# SPC1068 register map
File version: 20180100_70611510
CPU: CM3 r2p1, little endian, MPU, no FPU, 4 interrupt priority bits
Registers are 32-bit, read-write, reset 0x0 unless marked. A register's access mark holds for its fields unless they carry their own. Offsets are from the block's base; [hi:lo] are bit positions; 'fields as' and 'values as' point back to an identical list.

## I2C
Base 0x40006000
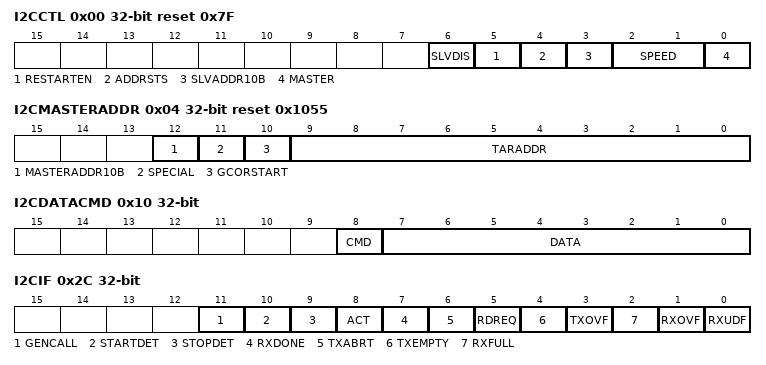
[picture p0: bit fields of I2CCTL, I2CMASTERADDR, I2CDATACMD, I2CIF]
0x00 I2CCTL reset 0x7F — I2C Control Register
  [6] SLVDIS — This bit controls whether I2C has its slave disabled, which means once the presetn signal is applied, then this bit takes on the value of the configuration parameter SLAVE_DISABLE. You have the choice of having the slave enabled or disabled after reset is applied, which means software does not have to configure the slave. By default, the slave is always enabled (in reset state as well). If you need to disable it after reset, set this bit to 1. If this bit is set (slave is disabled), I2C functions only as a master and does not perform any action that requires a slave. NOTE: Software should ensure that if this bit is written with 0, then bit 0 should also be written with a 0.
    0=SLAVE_ENABLE (Slave is enabled); 1=SLAVE_DISABLE (Slave is disabled)
  [5] RESTARTEN — Determines whether RESTART conditions may be sent when acting as a master. Some older slaves do not support handling RESTART conditions; however, RESTART conditions are used in several I2C operations. When RESTART is disabled, the master is prohibited from performing the following functions: - Change direction within a transfer (split) - Send a START BYTE - High-speed mode operation - Combined format transfers in 7-bit addressing modes - Read operation with a 10-bit address - Send multiple bytes per transfer By replacing RESTART condition followed by a STOP and a subsequent START condition, split operations are broken down into multiple I2C transfers. If the above operations are performed, it will result in setting bit 6 (TXABRT) of the I2CRAWIF register.
    0=DISABLE; 1=ENABLE
  [4] ADDRSTS ro — The function of this bit is handled by bit 12 of I2CMASTERADDR register, and becomes a read-only copy.
    0=7BIT_ADDR (7-bit addressing); 1=10BIT_ADDR (10-bit addressing)
  [3] SLVADDR10B — When acting as a slave, this bit controls whether the I2C responds to 7- or 10-bit addresses. 0x0: 7-bit addressing. The I2C ignores transactions that involve 10-bit addressing; for 7-bit addressing, only the lower 7 bits of the I2CSLVADDR register are compared. 0x1: 10-bit addressing. The I2C responds to only 10-bit addressing transfers that match the full 10 bits of the I2CSLVADDR register.
    values as ADDRSTS
  [2:1] SPEED — These bits control at which speed the I2C operates; its setting is relevant only if one is operating the I2C in master mode. Hardware protects against illegal values being programmed by software. This register should be programmed only with a value in the range of 1 to 3; otherwise, hardware updates this register with the value of 3.
    1=100K_BPS (Standard mode (100 kbit/s)); 2=400K_BPS (Fast mode (400 kbit/s)); 3=3400K_BPS (High speed mode (3.4 Mbit/s))
  [0] MASTER — This bit controls whether the I2C master is enabled. NOTE: Software should ensure that if this bit is written with '1' then bit 6 should also be written with a '1'.
    0=DISABLE (Master disabled); 1=ENABLE (Master enabled)
0x04 I2CMASTERADDR reset 0x1055 — I2C Master Address Register
  [12] MASTERADDR10B — This bit controls whether the I2C starts its transfers in 7- or 10-bit addressing mode when acting as a master.
    values as I2CCTL.ADDRSTS
  [11] SPECIAL — This bit indicates whether software performs a General Call or START BYTE command.
    0=DISABLE (Ignore bit 10 GCORSTART and use I2CMASTERADDR normally); 1=ENABLE (Perform special I2C command as specified in GCORSTART bit)
  [10] GCORSTART — If bit 11 (SPECIAL) is set to 1, then this bit indicates whether a General Call or START byte command is to be performed by the I2C.
    0=GENERAL_CALL (General Call Address after issuing a General Call, only writes may be performed. Attempting to issue a read command results in setting bit 6 (TXABRT) of the I2CRAWIF register. The I2C remains in General Call mode until the SPECIAL bit value (bit 11) is cleared); 1=START (START BYTE)
  [9:0] TARADDR — This is the target address for any master transaction. When transmitting a General Call, these bits are ignored. To generate a START BYTE, the CPU needs to write only once into these bits. If the I2CMASTERADDR and I2CSLVADDR are the same, loopback exists but the FIFOs are shared between master and slave, so full loopback is not feasible. Only one direction loopback mode is supported (simplex), not duplex. A master cannot transmit to itself; it can transmit to only a slave.
0x08 I2CSLVADDR reset 0x55 — I2C Slave Address Register
  [9:0] VAL — The VAL holds the slave address when the I2C is operating as a slave. For 7-bit addressing, only VAL[6:0] is used. This register can be written only when the I2C interface is disabled, which corresponds to the I2CENABLE register being set to 0. Writes at other times have no effect. Note: The default values cannot be any of the reserved address locations: that is, 0x00 to 0x07, or 0x78 to 0x7f. The correct operation of the device is not guaranteed if you program the I2CSLVADDR or I2CMASTERADDR to a reserved value.
0x0C I2CHSMADDR reset 0x1 — I2C High Speed Master Mode Code Address Register
  [2:0] VAL — This bit field holds the value of the I2C HS mode master code. HS-mode master codes are reserved 8-bit codes (00001xxx) that are not used for slave addressing or other purposes. Each master has its unique master code; up to eight high-speed mode masters can be present on the same I2C bus system. Valid values are from 0 to 7. This register can be written only when the I2C interface is disabled, which corresponds to the I2CENABLE register being set to 0. Writes at other times have no effect.
0x10 I2CDATACMD — I2C Data Buffer and Command Register
  [8] CMD — This bit controls whether a read or a write is performed. This bit does not control the direction when the I2C acts as a slave. It controls only the direction when it acts as a master. When a command is entered in the TX FIFO, this bit distinguishes the write and read commands. In slavereceiver mode, this bit is a 'don't care' because writes to this register are not required. In slave-transmitter mode, a '0' indicates that CPU data is to be transmitted and as DATA or I2CDATACMD[7:0]. When programming this bit, you should remember the following: attempting to perform a read operation after a General Call command has been sent results in a TXABRT interrupt (bit 6 of the I2CRAWIF register), unless bit 11 (SPECIAL) in the I2CMASTERADDR register has been cleared. If a '1' is written to this bit after receiving a RDREQ interrupt, then a TXABRT interrupt occurs. NOTE: It is possible that while attempting a master I2C read transfer on I2C, a RDREQ interrupt may have occurred simultaneously due to a remote I2C master addressing I2C. In this type of scenario, I2C ignores the I2CDATACMD write, generates a TXABRT interrupt, and waits to service the RDREQ interrupt.
    0=WRITE; 1=READ
  [7:0] DATA — This register contains the data to be transmitted or received on the I2C bus. If you are writing to this register and want to perform a read, bits 7:0 (DATA) are ignored by the I2C. However, when you read this register, these bits return the value of data received on the I2C interface.
0x14 I2CSSHCNT reset 0x1F4 — Standard Speed I2C Clock SCL High Count Register
  [15:0] VAL — This register must be set before any I2C bus transaction can take place to ensure proper I/O timing. This register sets the SCL clock high-period count for standard speed. These values apply only if the ic_clk is set to the given frequency in the table. This register can be written only when the I2C interface is disabled which corresponds to the I2CENABLE register being set to 0. Writes at other times have no effect. The minimum valid value is 6; hardware prevents values less than this being written, and if attempted results in 6 being set. For designs with APB_DATA_WIDTH = 8, the order of programming is important to ensure the correct operation of the I2C. The lower byte must be programmed first. Then the upper byte is programmed.
0x18 I2CSSLCNT reset 0x24C — Standard Speed I2C Clock SCL Low Count Register
  [15:0] VAL — This register must be set before any I2C bus transaction can take place to ensure proper I/O timing. This register sets the SCL clock low period count for standard speed. The table below shows some sample I2CSSLCNT calculations. These values apply only if the ic_clk is set to the given frequency in the table. This register can be written only when the I2C interface is disabled which corresponds to the I2CENABLE register being set to 0. Writes at other times have no effect. The minimum valid value is 8; hardware prevents values less than this being written, and if attempted, results in 8 being set. For designs with APB_DATA_WIDTH = 8, the order of programming is important to ensure the correct operation of I2C. The lower byte must be programmed first, and then the upper byte is programmed.
0x1C I2CFSHCNT reset 0x4B — Fast Speed I2C Clock SCL High Count Register
  [15:0] VAL — This register must be set before any I2C bus transaction can take place to ensure proper I/O timing. This register sets the SCL clock high-period count for fast speed. It is used in high-speed mode to send the Master Code and START BYTE or General CALL. This register can be written only when the I2C interface is disabled, which corresponds to the I2CENABLE register being set to 0. Writes at other times have no effect. The minimum valid value is 6; hardware prevents values less than this being written, and if attempted results in 6 being set. For designs with APB_DATA_WIDTH == 8 the order of programming is important to ensure the correct operation of the I2C. The lower byte must be programmed first. Then the upper byte is programmed.
0x20 I2CFSLCNT reset 0xA3 — Fast Speed I2C Clock SCL Low Count Register
  [15:0] VAL — This register must be set before any I2C bus transaction can take place to ensure proper I/O timing. This register sets the SCL clock low period count for fast speed. It is used in high-speed mode to send the Master Code and START BYTE or General CALL. This register can be written only when the I2C interface is disabled, which corresponds to theI2CENABLE register being set to 0. Writes at other times have no effect. The minimum valid value is 8; hardware prevents values less than this being written, and if attempted results in 8 being set. For designs with APB_DATA_WIDTH = 8 the order of programming is important to ensure the correct operation of the I2C. The lower byte must be programmed first. Then the upper byte is programmed. If the value is less than 8 then the count value gets changed to 8.
0x24 I2CHSHCNT reset 0x8 — High Speed I2C Clock SCL High Count Register
  [15:0] VAL — This register must be set before any I2C bus transaction can take place to ensure proper I/O timing. This register sets the SCL clock high period count for high speed. The SCL High time depends on the loading of the bus. For 100pF loading, the SCL High time is 60ns; for 400pF loading, the SCL High time is 120ns. This register can be written only when the I2C interface is disabled, which corresponds to the I2CENABLE register being set to 0. Writes at other times have no effect. The minimum valid value is 6; hardware prevents values less than this being written, and if attempted results in 6 being set. For designs with APB_DATA_WIDTH = 8 the order of programming is important to ensure the correct operation of the I2C. The lower byte must be programmed first. Then the upper byte is programmed.
0x28 I2CHSLCNT reset 0x14 — High Speed I2C Clock SCL Low Count Register
  [15:0] VAL — This register must be set before any I2C bus transaction can take place to ensure proper I/O timing. This register sets the SCL clock low period count for high speed. The SCL low time depends on the loading of the bus. For 100pF loading, the SCL low time is 160ns; for 400pF loading, the SCL low time is 320ns. This register can be written only when the I2C interface is disabled, which corresponds to the I2CENABLE register being set to 0. Writes at other times have no effect. The minimum valid value is 8; hardware prevents values less than this being written, and if attempted results in 8 being set. For designs with APB_DATA_WIDTH == 8 the order of programming is important to ensure the correct operation of the I2C. The lower byte must be programmed first. Then the upper byte is programmed. If the value is less than 8 then the count value gets changed to 8.
0x2C I2CIF ro — I2C Interrupt Flag Register
  [all] fields
    0=NOT_OCCUR (None); 1=OCCUR (None)
  [11] GENCALL — Set only when a General Call address is received and it is acknowledged. It stays set until it is cleared either by disabling I2C or when the CPU reads bit 0 of the I2CGENCALLCLR register. I2C stores the received data in the Rx buffer.
  [10] STARTDET — Indicates whether a START or RESTART condition has occurred on the I2C interface regardless of whether I2C is operating in slave or master mode.
  [9] STOPDET — Indicates whether a STOP condition has occurred on the I2C interface regardless of whether I2C is operating in slave or master mode.
  [8] ACT — This bit captures I2C activity and stays set until it is cleared. There are four ways to clear it: - Disabling the I2C - Reading the I2CACTCLR register - Reading the I2CINTCLR register - System reset. Once this bit is set, it stays set unless one of the four methods is used to clear it. Even if the I2C module is idle, this bit remains set until cleared, indicating that there was activity on the bus.
  [7] RXDONE — When the I2C is acting as a slave-transmitter, this bit is set to 1 if the master does not acknowledge a transmitted byte. This occurs on the last byte of the transmission, indicating that the transmission is done.
  [6] TXABRT — This bit indicates if I2C, as an I2C transmitter, is unable to complete the intended actions on the contents of the transmit FIFO. This situation can occur both as an I2C master or an I2C slave, and is referred to as a 'transmit abort'. When this bit is set to 1, the I2CTXABRTSRC register indicates the reason why the transmit abort takes places. NOTE: The I2C flushes/resets/empties the TX FIFO whenever this bit is set. The TX FIFO remains in this flushed state until the register I2CTXABRTCLR is read. Once this read is performed, the TX FIFO is then ready to accept more data bytes from the APB interface.
  [5] RDREQ — This bit is set to 1 when I2C is acting as a slave and another I2C master is attempting to read data from I2C. The I2C holds the I2C bus in a wait state (SCL=0) until this interrupt is serviced, which means that the slave has been addressed by a remote master that is asking for data to be transferred. The processor must respond to this interrupt and then write the requested data to the I2CDATACMD register. This bit is set to 0 just after the processor reads the I2CRDREQCLR register.
  [4] TXEMPTY — This bit is set to 1 when the transmit buffer is at or below the threshold value set in the I2CTXTH register. It is automatically cleared by hardware when the buffer level goes above the threshold. When the I2CENABLE bit 0 is 0, the TX FIFO is flushed and held in reset. There the TX FIFO looks like it has no data within it, so this bit is set to 1, provided there is activity in the master or slave state machines. When there is no longer activity, then with ic_en=0, this bit is set to 0.
  [3] TXOVF — Set during transmit if the transmit buffer is filled to TX_BUFFER_DEPTH and the processor attempts to issue another I2C command by writing to the I2CDATACMD register. When the module is disabled, this bit keeps its level until the master or slave state machines go into idle, and when ic_en goes to 0, this interrupt is cleared.
  [2] RXFULL — Set when the receive buffer reaches or goes above the threshold in the I2CRXTH register. It is automatically cleared by hardware when buffer level goes below the threshold. If the module is disabled (I2CENABLE[0]=0), the RX FIFO is flushed and held in reset; therefore the RX FIFO is not full. So this bit is cleared once the I2CENABLE bit 0 is programmed with a 0, regardless of the activity that continues.
  [1] RXOVF — Set if the receive buffer is completely filled to RX_BUFFER_DEPTH and an additional byte is received from an external I2C device. The I2C acknowledges this, but any data bytes received after the FIFO is full are lost. If the module is disabled (I2CENABLE[0]=0), this bit keeps its level until the master or slave state machines go into idle, and when ic_en goes to 0, this interrupt is cleared.
  [0] RXUDF — Set if the processor attempts to read the receive buffer when it is empty by reading from the I2CDATACMD register. If the module is disabled (I2CENABLE[0]=0), this bit keeps its level until the master or slave state machines go into idle, and when ic_en goes to 0, this interrupt is cleared.
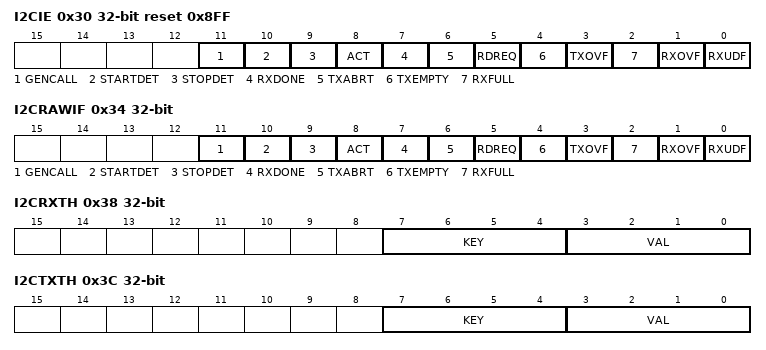
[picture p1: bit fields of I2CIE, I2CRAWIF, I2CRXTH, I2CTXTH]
0x30 I2CIE reset 0x8FF — I2C Interrupt Enable Register
  [11] GENCALL — Enable/disable GENCALL interrupt
    0=DISABLE (Disable GENCALL interrupt); 1=ENABLE (Enable GENCALL interrupt)
  [10] STARTDET — Enable/disable STARTDET interrupt
    0=DISABLE (Disable STARTDET interrupt); 1=ENABLE (Enable STARTDET interrupt)
  [9] STOPDET — Enable/disable STOPDET interrupt
    0=DISABLE (Disable STOPDET interrupt); 1=ENABLE (Enable STOPDET interrupt)
  [8] ACT — Enable/disable ACTIVITY interrupt
    0=DISABLE (Disable ACTIVITY interrupt); 1=ENABLE (Enable ACTIVITY interrupt)
  [7] RXDONE — Enable/disable RXDONE interrupt
    0=DISABLE (Disable RXDONE interrupt); 1=ENABLE (Enable RXDONE interrupt)
  [6] TXABRT — Enable/disable TXABRT interrupt
    0=DISABLE (Disable TXABRT interrupt); 1=ENABLE (Enable TXABRT interrupt)
  [5] RDREQ — Enable/disable RDREQ interrupt
    0=DISABLE (Disable RDREQ interrupt); 1=ENABLE (Enable RDREQ interrupt)
  [4] TXEMPTY — Enable/disable TXEMPTY interrupt
    0=DISABLE (Disable TXEMPTY interrupt); 1=ENABLE (Enable TXEMPTY interrupt)
  [3] TXOVF — Enable/disable TXOVF interrupt
    0=DISABLE (Disable TXOVF interrupt); 1=ENABLE (Enable TXOVF interrupt)
  [2] RXFULL — Enable/disable RXFULL interrupt
    0=DISABLE (Disable RXFULL interrupt); 1=ENABLE (Enable RXFULL interrupt)
  [1] RXOVF — Enable/disable RXOVF interrupt
    0=DISABLE (Disable RXOVF interrupt); 1=ENABLE (Enable RXOVF interrupt)
  [0] RXUDF — Enable/disable RXUDF interrupt
    0=DISABLE (Disable RXUDF interrupt); 1=ENABLE (Enable RXUDF interrupt)
0x34 I2CRAWIF ro — I2C Raw Interrupt Flag Register
  [11] GENCALL — Set only when a General Call address is received and it is acknowledged. It stays set until it is cleared either by disabling I2C or when the CPU reads bit 0 of the I2CGENCALLCLR register. I2C stores the received data in the Rx buffer.
    0=NOT_OCCUR (None); 1=OCCUR (None)
  [10] STARTDET — Indicates whether a START or RESTART condition has occurred on the I2C interface regardless of whether I2C is operating in slave or master mode.
    0=NOT_OCCUR (None); 1=OCCUR (None)
  [9] STOPDET — Indicates whether a STOP condition has occurred on the I2C interface regardless of whether I2C is operating in slave or master mode.
    0=NOT_OCCUR (None); 1=OCCUR (None)
  [8] ACT — This bit captures I2C activity and stays set until it is cleared. There are four ways to clear it: - Disabling the I2C - Reading the I2CACTCLR register - Reading the I2CINTCLR register - System reset. Once this bit is set, it stays set unless one of the four methods is used to clear it. Even if the I2C module is idle, this bit remains set until cleared, indicating that there was activity on the bus.
    0=NOT_OCCUR (None); 1=OCCUR (None)
  [7] RXDONE — When the I2C is acting as a slave-transmitter, this bit is set to 1 if the master does not acknowledge a transmitted byte. This occurs on the last byte of the transmission, indicating that the transmission is done.
    0=NOT_OCCUR (None); 1=OCCUR (None)
  [6] TXABRT — This bit indicates if I2C, as an I2C transmitter, is unable to complete the intended actions on the contents of the transmit FIFO. This situation can occur both as an I2C master or an I2C slave, and is referred to as a 'transmit abort'. When this bit is set to 1, the I2CTXABRTSRC register indicates the reason why the transmit abort takes places. NOTE: The I2C flushes/resets/empties the TX FIFO whenever this bit is set. The TX FIFO remains in this flushed state until the register I2CTXABRTCLR is read. Once this read is performed, the TX FIFO is then ready to accept more data bytes from the APB interface.
    0=NOT_OCCUR (None); 1=OCCUR (None)
  [5] RDREQ — This bit is set to 1 when I2C is acting as a slave and another I2C master is attempting to read data from I2C. The I2C holds the I2C bus in a wait state (SCL=0) until this interrupt is serviced, which means that the slave has been addressed by a remote master that is asking for data to be transferred. The processor must respond to this interrupt and then write the requested data to the I2CDATACMD register. This bit is set to 0 just after the processor reads the I2CRDREQCLR register.
    1=OCCUR (None)
  [4] TXEMPTY — This bit is set to 1 when the transmit buffer is at or below the threshold value set in the I2CTXTH register. It is automatically cleared by hardware when the buffer level goes above the threshold. When the I2CENABLE bit 0 is 0, the TX FIFO is flushed and held in reset. There the TX FIFO looks like it has no data within it, so this bit is set to 1, provided there is activity in the master or slave state machines. When there is no longer activity, then with ic_en=0, this bit is set to 0.
    0=NOT_OCCUR (None)
  [3] TXOVF — Set during transmit if the transmit buffer is filled to TX_BUFFER_DEPTH and the processor attempts to issue another I2C command by writing to the I2CDATACMD register. When the module is disabled, this bit keeps its level until the master or slave state machines go into idle, and when ic_en goes to 0, this interrupt is cleared.
    0=NOT_OCCUR (None)
  [2] RXFULL — Set when the receive buffer reaches or goes above the threshold value in the I2CRXTH register. It is automatically cleared by hardware when buffer level goes below the threshold. If the module is disabled (I2CENABLE[0]=0), the RX FIFO is flushed and held in reset; therefore the RX FIFO is not full. So this bit is cleared once the I2CENABLE bit 0 is programmed with a 0, regardless of the activity that continues.
    0=NOT_OCCUR (None)
  [1] RXOVF — Set if the receive buffer is completely filled to RX_BUFFER_DEPTH and an additional byte is received from an external I2C device. The I2C acknowledges this, but any data bytes received after the FIFO is full are lost. If the module is disabled (I2CENABLE[0]=0), this bit keeps its level until the master or slave state machines go into idle, and when ic_en goes to 0, this interrupt is cleared.
    0=NOT_OCCUR (None); 1=OCCUR (None)
  [0] RXUDF — Set if the processor attempts to read the receive buffer when it is empty by reading from the I2CDATACMD register. If the module is disabled (I2CENABLE[0]=0), this bit keeps its level until the master or slave state machines go into idle, and when ic_en goes to 0, this interrupt is cleared.
    0=NOT_OCCUR (None); 1=OCCUR (None)
0x38 I2CRXTH — I2C Receive FIFO Threshold Register
  [7:4] KEY wo — Must write 0x0 to this field when write to low LSBs, else LSBs is always 0xF. Always readback 0
  [3:0] VAL — Receive FIFO Threshold Level. Controls the level of entries (or above) that triggers the RXFULL interrupt (bit 2 in I2CRAWIF register). The valid range is 0-255, with the additional restriction that hardware does not allow this value to be set to a value larger than the depth of the buffer. If an attempt is made to do that, the actual value set will be the maximum depth of the buffer. A value of 0 sets the threshold for 1 entry, and a value of 255 sets the threshold for 256 entries.
0x3C I2CTXTH — I2C Transmit FIFO Threshold Register
  [7:4] KEY wo — Must write 0x0 to this field when write to low LSBs, else LSBs is always 0xF. Always readback 0
  [3:0] VAL — Transmit FIFO Threshold Level. Controls the level of entries (or below) that trigger the TXEMPTY interrupt (bit 4 in I2CRAWIF register). The valid range is 0-255, with the additional restriction that it may not be set to value larger than the depth of the buffer. If an attempt is made to do that, the actual value set will be the maximum depth of the buffer. A value of 0 sets the threshold for 0 entries, and a value of 255 sets the threshold for 255 entries.
0x40 I2CINTCLR ro — Clear Combined and Individual Interrupt Register
  [0] CLR — Read this register to clear the combined interrupt, all individual interrupts, and the I2CTXABRTSRC register. This bit does not clear hardware clearable interrupts but software clearable interrupts. Refer to Bit 9 of the I2CTXABRTSRC register for an exception to clearing TX_ABRT_SOURCE.
    0=Read to clear
0x44 I2CRXUDFCLR ro — Clear RXUDF Interrupt Register
  [0] CLR — Read this register to clear the RXUDF interrupt (bit 0) of the I2CRAWIF register. Reset value: 0x0
    0=Read to clear
0x48 I2CRXOVFCLR ro — Clear RXOVF Interrupt Register
  [0] CLR — Read this register to clear the RXOVF interrupt (bit 1) of the I2CRAWIF register
    0=Read to clear
0x4C I2CTXOVFCLR ro — Clear TXOVF Interrupt Register
  [0] CLR — Read this register to clear the TXOVF interrupt (bit 3) of the I2CRAWIF register
    0=Read to clear
0x50 I2CRDREQCLR ro — Clear RDREQ Interrupt Register
  [0] CLR — Read this register to clear the RDREQ interrupt (bit 5) of the I2CRAWIF register
    0=Read to clear
0x54 I2CTXABRTCLR ro — Clear TXABRT Interrupt Register
  [0] CLR — Read this register to clear the TXABRT interrupt (bit 6) of the I2CRAWIF register, and the I2CTXABRTSRC register. This also releases the TX FIFO from the flushed/reset state, allowing more writes to the TX FIFO. Refer to Bit 9 of the I2CTXABRTSRC register for an exception to clearing TX_ABRT_SOURCE.
    0=Read to clear
0x58 I2CRXDONECLR ro — Clear RXDONE Interrupt Register
  [0] CLR — Read this register to clear the RXDONE interrupt (bit 7) of the I2CRAWIF register
    0=Read to clear
0x5C I2CACTCLR ro — Clear ACT Interrupt Register
  [0] CLR — Reading this register clears the ACT interrupt if the I2C is not active anymore. If the I2C module is still active on the bus, the ACTIVITY interrupt bit continues to be set. It is automatically cleared by hardware if the module is disabled and if there is no further activity on the bus. The value read from this register to get status of the ACT interrupt (bit 8) of the I2CRAWIF register.
    0=Read to clear
0x60 I2CSTOPDETCLR ro — Clear STOPDET Interrupt Register
  [0] CLR — Read this register to clear the STOPDET interrupt (bit 9) of the I2CRAWIF register
    0=Read to clear
0x64 I2CSTARTDETCLR ro — Clear STARTDET Interrupt Register
  [0] CLR — Read this register to clear the STARTDET interrupt (bit 10) of the I2CRAWIF register
    0=Read to clear
0x68 I2CGENCALLCLR ro — Clear GENCALL Interrupt Register
  [0] CLR — Read this register to clear the GENCALL interrupt (bit 11) of I2CRAWIF register.
    0=Read to clear
0x6C I2CENABLE
  [0] EN — Controls whether the I2C is enabled. 0x0: Disables I2C (TX and RX FIFOs are held in an erased state). Software can disable I2C while it is active. However, it is important that care be taken to ensure that i2c is disabled properly. When I2C is disabled, the following occurs: - The TX FIFO and RX FIFO get flushed. - Status bits in the I2CIF register are still active until i2c goes into IDLE state. If the module is transmitting, it stops as well as deletes the contents of the transmit buffer after the current transfer is complete. If the module is receiving, the I2C stops the current transfer at the end of the current byte and does not acknowledge the transfer. In systems with asynchronous pclk and ic_clk when CLK_TYPE parameter set to asynchronous, there is a two ic_clk delay when enabling or disabling the I2C.
    0=DISABLE (Disables I2C (TX and RX FIFOs are held in an erased state)); 1=ENABLE (Enables I2C)
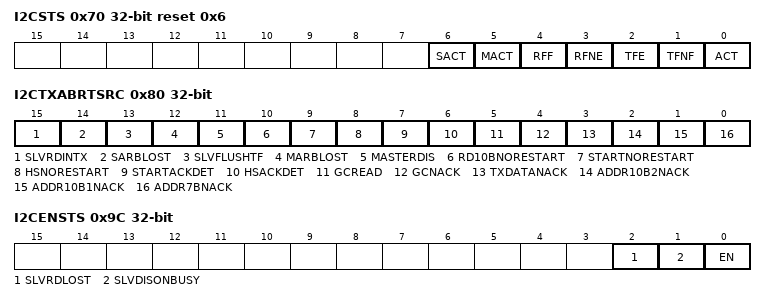
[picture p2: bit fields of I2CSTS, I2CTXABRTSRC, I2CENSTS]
0x70 I2CSTS ro reset 0x6 — I2C Status Register
  [6] SACT — Slave FSM Activity Status. When the Slave Finite State Machine (FSM) is not in the IDLE state, this bit is set.
    0=NOT_OCCUR (Slave FSM is in IDLE state so the Slave part of I2C is not Active); 1=OCCUR (Slave FSM is not in IDLE state so the Slave part of I2C is Active)
  [5] MACT — Master FSM Activity Status. When the Master Finite State Machine (FSM) is not in the IDLE state, this bit is set. Note: I2CSTS[0]-that is, ACT bit-is the OR of SACT and MACT bits.
    0=NOT_OCCUR (Master FSM is in IDLE state so the Master part of I2C is not Active); 1=OCCUR (Master FSM is not in IDLE state so the Master part of I2C is Active)
  [4] RFF — Receive FIFO Completely Full. When the receive FIFO is completely full, this bit is set. When the receive FIFO contains one or more empty location, this bit is cleared.
    0=NOT_OCCUR (Receive FIFO is not full); 1=OCCUR (Receive FIFO is full)
  [3] RFNE — Receive FIFO Not Empty. This bit is set when the receive FIFO contains one or more entries; it is cleared when the receive FIFO is empty.
    0=NOT_OCCUR (Receive FIFO is empty); 1=OCCUR (Receive FIFO is not empty)
  [2] TFE — Transmit FIFO Completely Empty. When the transmit FIFO is completely empty, this bit is set. When it contains one or more valid entries, this bit is cleared. This bit field does not request.
    0=NOT_OCCUR (Transmit FIFO is not empty); 1=OCCUR (Transmit FIFO is empty)
  [1] TFNF — Transmit FIFO Not Full. Set when the transmit FIFO contains one or more empty locations, and is cleared when the FIFO is full.
    0=NOT_OCCUR (Transmit FIFO is full); 1=OCCUR (Transmit FIFO is not full)
  [0] ACT — I2C Activity Status. Reset value: 0x0
    0=NOT_OCCUR (Idle); 1=OCCUR (Active)
0x74 I2CTFLVL ro — I2C Transmit FIFO Level Register
  [4:0] VAL — Transmit FIFO Level. Contains the number of valid data entries in the transmit FIFO.
0x78 I2CRFLVL ro — I2C Receive FIFO Level Register
  [4:0] VAL — Receive FIFO Level. Contains the number of valid data entries in the receive FIFO.
0x80 I2CTXABRTSRC ro — I2C Transmit Abort Source Register
  [all] fields
    0=NOT_OCCUR (None); 1=OCCUR (None)
  [15] SLVRDINTX — Role of I2C: Slave-Transmitter. 0x1: When the processor side responds to a slave mode request for data to be transmitted to a remote master and user writes a 1 in CMD (bit 8) of I2CDATACMD register.
  [14] SARBLOST — Role of i2c: Slave-Transmitter. 0x1: Slave lost the bus while transmitting data to a remote master. I2CTXABRTSRC[12] is set at the same time. Note: Even though the slave never 'owns' the bus, something could go wrong on the bus. This is a failsafe check. For instance, during a data transmission at the low-to-high transition of SCL, if what is on the data bus is not what is supposed to be transmitted, then I2C no longer own the bus.
  [13] SLVFLUSHTF — Role of I2C: Slave-Transmitter. 0x1: Slave has received a read command and some data exists in the TX FIFO so the slave issues a TXABRT interrupt to flush old data in TX FIFO.
  [12] MARBLOST — Role of I2C: Master-Transmitter or Slave-Transmitter. 0x1: Master has lost arbitration, or if I2CTXABRTSRC[14] is also set, then the slave transmitter has lost arbitration. Note: I2C can be both master and slave at the same time.
  [11] MASTERDIS — Role of I2C: Master-Transmitter or Master-Receiver. 0x1: User tries to initiate a Master operation with the Master mode disabled.
  [10] RD10BNORESTART — Role of I2C: Master-Receiver. 0x1: The restart is disabled (RESTARTEN bit (I2CCTL[5]) =0) and the master sends a read command in 10-bit addressing mode.
  [9] STARTNORESTART — To clear Bit 9, the source of the ABRT_SBYTE_NORSTRT must be fixed first; restart must be enabled (I2CCTL[5]=1), the SPECIAL bit must be cleared (I2CMASTERADDR[11]), or the GCORSTART bit must be cleared (I2CMASTERADDR[10]). Once the source of the ABRT_SBYTE_NORSTRT is fixed, then this bit can be cleared in the same manner as other bits in this register. If the source of the ABRT_SBYTE_NORSTRT is not fixed before attempting to clear this bit, bit 9 clears for one cycle and then gets reasserted. Role of I2C: Master. 0x1: The restart is disabled (RESTARTEN bit (I2CCTL[5]) =0) and the user is trying to send a START Byte.
  [8] HSNORESTART — Role of I2C: Master-Transmitter or Master-Receiver. 0x1: The restart is disabled (RESTARTEN bit (I2CCTL[5]) =0) and the user is trying to use the master to transfer data in High Speed mode.
  [7] STARTACKDET — Role of I2C: Master. 0x1: Master has sent a START Byte and the START Byte was acknowledged (wrong behavior).
  [6] HSACKDET — Role of I2C: Master. 0x1: Master is in High Speed mode and the High Speed Master code was acknowledged (wrong behavior).
  [5] GCREAD — Role of I2C: Master-Transmitter. 0x1: I2C in master mode sent a General Call but the user programmed the byte following the General Call to be a read from the bus (I2CDATACMD[9] is set to 1).
  [4] GCNACK — Role of I2C: Master-Transmitter. 0x1: I2C in master mode sent a General Call and no slave on the bus acknowledged the General Call.
  [3] TXDATANACK — Role of I2C: Master-Transmitter. 0x1: This is a master-mode only bit. Master has received an acknowledgement for the address, but when it sent data byte(s) following the address, it did not receive an acknowledge from the remote slave(s).
  [2] ADDR10B2NACK — Role of I2C: Master-Transmitter or Master-Receiver. 0x1: Master is in 10-bit address mode and the second address byte of the 10-bit address was not acknowledged by any slave.
  [1] ADDR10B1NACK — Role of I2C: Master-Transmitter or Master-Receiver. 0x1: Master is in 10-bit address mode and the first 10-bit address byte was not acknowledged by any slave.
  [0] ADDR7BNACK — Role of I2C: Master-Transmitter or Master-Receiver. 0x1: Master is in 7-bit addressing mode and the address sent was not acknowledged by any slave.
0x94 I2CSDASETUP reset 0x64
  [7:0] VAL — SDA Setup. It is recommended that if the required delay is 1000ns, then for an ic_clk frequency of 10 MHz, SDA_SETUP should be programmed to a value of 11.
0x98 I2CACKGC reset 0x1 — I2C ACK General Call Register
  [0] ACKGC — ACK General Call. When set to 1, I2C responds with a ACK (by asserting ic_data_oe) when it receives a General Call. Otherwise, I2C responds with a NACK (by negating ic_data_oe).
    0=DISABLE (I2C responds with a NACK); 1=ENABLE (I2C responds with a ACK)
0x9C I2CENSTS ro — I2C Enable Status Register
  [2] SLVRDLOST — Slave Received Data Lost. This bit indicates if a Slave-Receiver operation has been aborted with at least one data byte received from an I2C transfer due to the setting of I2CENABLE from 1 to 0. When read as 1, I2C is deemed to have been actively engaged in an aborted I2C transfer (with matching address) and the data phase of the I2C transfer has been entered, even though a data byte has been responded with a NACK. NOTE: If the remote I2C master terminates the transfer with a STOP condition before the I2C has a chance to NACK a transfer, and I2CENABLE has been set to 0, then this bit is also set to 1. When read as 0, I2C is deemed to have been disabled without being actively involved in the data phase of a Slave-Receiver transfer. NOTE: The CPU can safely read this bit when EN (bit 0) is read as 0.
    0=NOT_OCCUR (None); 1=OCCUR (None)
  [1] SLVDISONBUSY — Slave Disabled While Busy (Transmit, Receive). This bit indicates if a potential or active Slave operation has been aborted due to the setting of the I2CENABLE register from 1 to 0. This bit is set when the CPU writes a 0 to the I2CENABLE register while: (a) I2C is receiving the address byte of the Slave-Transmitter operation from a remote master; OR, (b) address and data bytes of the Slave-Receiver operation from a remote master. When read as 1, I2C is deemed to have forced a NACK during any part of an I2C transfer, irrespective of whether the I2C address matches the slave address set in I2C (SAR register) OR if the transfer is completed before I2CENABLE is set to 0 but has not taken effect. NOTE: If the remote I2C master terminates the transfer with a STOP condition before the i2c has a chance to NACK a transfer, and I2CENABLE has been set to 0, then this bit will also be set to 1. When read as 0, I2C is deemed to have been disabled when there is master activity, or when the I2C bus is idle. NOTE: The CPU can safely read this bit when EN (bit 0) is read as 0.
    0=NOT_OCCUR (None); 1=OCCUR (None)
  [0] EN — ic_en Status. This bit always reflects the value driven on the output port ic_en. When read as 1, I2C is deemed to be in an enabled state. When read as 0, I2C is deemed completely inactive. NOTE: The CPU can safely read this bit anytime. When this bit is read as 0, the CPU can safely read SLVRDLOST (bit 2) and SLVDISONBUSY (bit 1).
    0=NOT_OCCUR (I2C is deemed completely inactive); 1=OCCUR (I2C is deemed to be in an enabled state)
